AUTOSAR XML (schema 4-2-1)
package /RootP_ASWC_A7D2
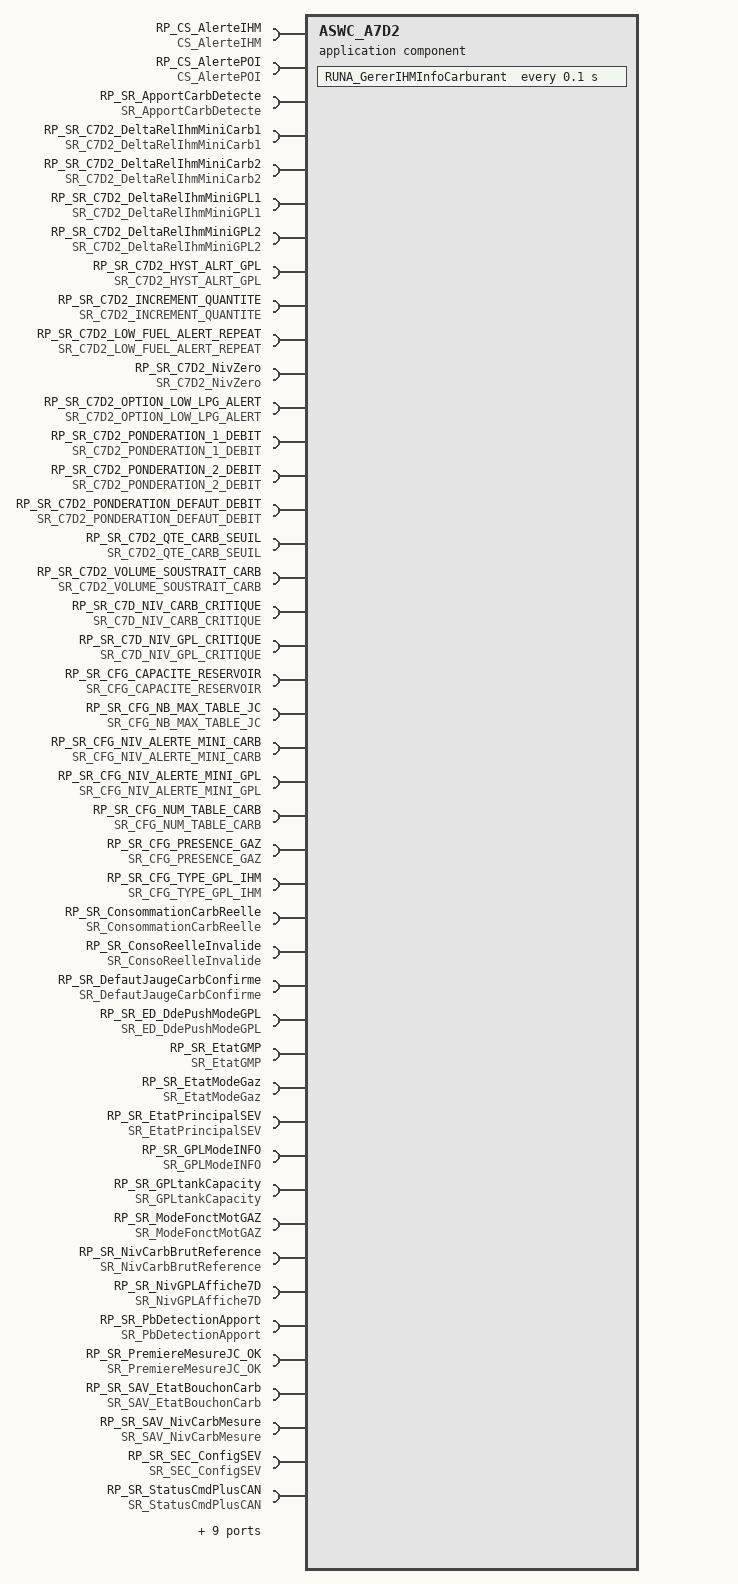
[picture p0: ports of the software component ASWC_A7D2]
  application sw component type ASWC_A7D2
    9 x provide/require port:
      PRP_SR_CapaciteReservoirJCA: nonqueued-receiver-com-spec{data-element=CapaciteReservoirJCA, enable-update=0, handle-data-status=1, handle-never-received=0, init-value=CONST_tBYTE_0:0}, provided-required-interface=SR_CapaciteReservoirJCA
      PRP_SR_DdeVoyMiniCarburant: nonqueued-receiver-com-spec{data-element=DdeVoyMiniCarburant, enable-update=0, handle-data-status=1, handle-never-received=0, init-value=CONST_tLOG_0:0}, provided-required-interface=SR_DdeVoyMiniCarburant
      PRP_SR_DdeVoyMiniCarburantClig: nonqueued-receiver-com-spec{data-element=DdeVoyMiniCarburantClig, enable-update=0, handle-data-status=1, handle-never-received=0, init-value=CONST_t_cDemande_0:0}, provided-required-interface=SR_DdeVoyMiniCarburantClig
      PRP_SR_MiniCarburant: nonqueued-receiver-com-spec{data-element=MiniCarburant, enable-update=0, handle-data-status=1, handle-never-received=0, init-value=CONST_tLOG_0:0}, provided-required-interface=SR_MiniCarburant
      PRP_SR_MiniGPL: nonqueued-receiver-com-spec{data-element=MiniGPL, enable-update=0, handle-data-status=1, handle-never-received=0, init-value=CONST_tLOG_0:0}, provided-required-interface=SR_MiniGPL
      PRP_SR_MiniGPLCritique: nonqueued-receiver-com-spec{data-element=MiniGPLCritique, enable-update=0, handle-data-status=1, handle-never-received=0, init-value=CONST_tLOG_0:0}, provided-required-interface=SR_MiniGPLCritique
      PRP_SR_NivCarbAfficheVersCmb: nonqueued-receiver-com-spec{data-element=NivCarbAfficheVersCmb, enable-update=0, handle-data-status=1, handle-never-received=0, init-value=CONST_tBYTE_0:0}, provided-required-interface=SR_NivCarbAfficheVersCmb
      PRP_SR_NivCarbMesureConverti: nonqueued-receiver-com-spec{data-element=NivCarbMesureConverti, enable-update=0, handle-data-status=1, handle-never-received=0, init-value=CONST_tBYTE_0:0}, provided-required-interface=SR_NivCarbMesureConverti
      PRP_SR_SAV_NivCarbAffiche: nonqueued-receiver-com-spec{data-element=SAV_NivCarbAffiche, enable-update=0, handle-data-status=1, handle-never-received=0, init-value=CONST_tWORD_0xFFFF:65535}, provided-required-interface=SR_SAV_NivCarbAffiche
    53 x require port:
      RP_CS_AlerteIHM: required-interface=CS_AlerteIHM
      RP_CS_AlertePOI: required-interface=CS_AlertePOI
      RP_SR_ApportCarbDetecte: nonqueued-receiver-com-spec{data-element=ApportCarbDetecte, enable-update=0, handle-data-status=1, handle-never-received=0, init-value=CONST_tLOG_0:0}, required-interface=SR_ApportCarbDetecte
      RP_SR_C7D2_DeltaRelIhmMiniCarb1: nonqueued-receiver-com-spec{data-element=C7D2_DeltaRelIhmMiniCarb1, enable-update=0, handle-data-status=1, handle-never-received=0, init-value=CONST_t_C7D2_DeltaRelIhmMiniCarb1_50:50}, required-interface=SR_C7D2_DeltaRelIhmMiniCarb1
      RP_SR_C7D2_DeltaRelIhmMiniCarb2: nonqueued-receiver-com-spec{data-element=C7D2_DeltaRelIhmMiniCarb2, enable-update=0, handle-data-status=1, handle-never-received=0, init-value=CONST_t_C7D2_DeltaRelIhmMiniCarb2_25:25}, required-interface=SR_C7D2_DeltaRelIhmMiniCarb2
      RP_SR_C7D2_DeltaRelIhmMiniGPL1: nonqueued-receiver-com-spec{data-element=C7D2_DeltaRelIhmMiniGPL1, enable-update=0, handle-data-status=1, handle-never-received=0, init-value=CONST_tBYTE_50:50}, required-interface=SR_C7D2_DeltaRelIhmMiniGPL1
      RP_SR_C7D2_DeltaRelIhmMiniGPL2: nonqueued-receiver-com-spec{data-element=C7D2_DeltaRelIhmMiniGPL2, enable-update=0, handle-data-status=1, handle-never-received=0, init-value=CONST_tBYTE_25:25}, required-interface=SR_C7D2_DeltaRelIhmMiniGPL2
      RP_SR_C7D2_HYST_ALRT_GPL: nonqueued-receiver-com-spec{data-element=C7D2_HYST_ALRT_GPL, enable-update=0, handle-data-status=1, handle-never-received=0, init-value=CONST_t_C7D2_HYST_ALRT_GPL_2:2}, required-interface=SR_C7D2_HYST_ALRT_GPL
      RP_SR_C7D2_INCREMENT_QUANTITE: nonqueued-receiver-com-spec{data-element=C7D2_INCREMENT_QUANTITE, enable-update=0, handle-data-status=1, handle-never-received=0, init-value=CONST_tBYTE_37:37}, required-interface=SR_C7D2_INCREMENT_QUANTITE
      RP_SR_C7D2_LOW_FUEL_ALERT_REPEAT: nonqueued-receiver-com-spec{data-element=C7D2_LOW_FUEL_ALERT_REPEAT, enable-update=0, handle-data-status=1, handle-never-received=0, init-value=CONST_tLOG_0:0}, required-interface=SR_C7D2_LOW_FUEL_ALERT_REPEAT
      RP_SR_C7D2_NivZero: nonqueued-receiver-com-spec{data-element=C7D2_NivZero, enable-update=0, handle-data-status=1, handle-never-received=0, init-value=CONST_tBYTE_0:0}, required-interface=SR_C7D2_NivZero
      RP_SR_C7D2_OPTION_LOW_LPG_ALERT: nonqueued-receiver-com-spec{data-element=C7D2_OPTION_LOW_LPG_ALERT, enable-update=0, handle-data-status=1, handle-never-received=0, init-value=CONST_C7D2_OPTION_LOW_LPG_ALERT_t_cPosIdent_cPosIdent_Absent:0}, required-interface=SR_C7D2_OPTION_LOW_LPG_ALERT
      RP_SR_C7D2_PONDERATION_1_DEBIT: nonqueued-receiver-com-spec{data-element=C7D2_PONDERATION_1_DEBIT, enable-update=0, handle-data-status=1, handle-never-received=0, init-value=CONST_tBYTE_18:18}, required-interface=SR_C7D2_PONDERATION_1_DEBIT
      RP_SR_C7D2_PONDERATION_2_DEBIT: nonqueued-receiver-com-spec{data-element=C7D2_PONDERATION_2_DEBIT, enable-update=0, handle-data-status=1, handle-never-received=0, init-value=CONST_tBYTE_7:7}, required-interface=SR_C7D2_PONDERATION_2_DEBIT
      RP_SR_C7D2_PONDERATION_DEFAUT_DEBIT: nonqueued-receiver-com-spec{data-element=C7D2_PONDERATION_DEFAUT_DEBIT, enable-update=0, handle-data-status=1, handle-never-received=0, init-value=CONST_tBYTE_13:13}, required-interface=SR_C7D2_PONDERATION_DEFAUT_DEBIT
      RP_SR_C7D2_QTE_CARB_SEUIL: nonqueued-receiver-com-spec{data-element=C7D2_QTE_CARB_SEUIL, enable-update=0, handle-data-status=1, handle-never-received=0, init-value=CONST_tWORD_1250:1250}, required-interface=SR_C7D2_QTE_CARB_SEUIL
      RP_SR_C7D2_VOLUME_SOUSTRAIT_CARB: nonqueued-receiver-com-spec{data-element=C7D2_VOLUME_SOUSTRAIT_CARB, enable-update=0, handle-data-status=1, handle-never-received=0, init-value=CONST_tBYTE_0:0}, required-interface=SR_C7D2_VOLUME_SOUSTRAIT_CARB
      RP_SR_C7D_NIV_CARB_CRITIQUE: nonqueued-receiver-com-spec{data-element=C7D_NIV_CARB_CRITIQUE, enable-update=0, handle-data-status=1, handle-never-received=0, init-value=CONST_t_C7D_NIV_CARB_CRITIQUE_4:4}, required-interface=SR_C7D_NIV_CARB_CRITIQUE
      RP_SR_C7D_NIV_GPL_CRITIQUE: nonqueued-receiver-com-spec{data-element=C7D_NIV_GPL_CRITIQUE, enable-update=0, handle-data-status=1, handle-never-received=0, init-value=CONST_tBYTE_7:7}, required-interface=SR_C7D_NIV_GPL_CRITIQUE
      RP_SR_CFG_CAPACITE_RESERVOIR: nonqueued-receiver-com-spec{data-element=CFG_CAPACITE_RESERVOIR, enable-update=0, handle-data-status=1, handle-never-received=0, init-value=CONST_tBYTE_50:50}, required-interface=SR_CFG_CAPACITE_RESERVOIR
      RP_SR_CFG_NB_MAX_TABLE_JC: nonqueued-receiver-com-spec{data-element=CFG_NB_MAX_TABLE_JC, enable-update=0, handle-data-status=1, handle-never-received=0, init-value=CONST_tBYTE_15:15}, required-interface=SR_CFG_NB_MAX_TABLE_JC
      RP_SR_CFG_NIV_ALERTE_MINI_CARB: nonqueued-receiver-com-spec{data-element=CFG_NIV_ALERTE_MINI_CARB, enable-update=0, handle-data-status=1, handle-never-received=0, init-value=CONST_tBYTE_20:20}, required-interface=SR_CFG_NIV_ALERTE_MINI_CARB
      RP_SR_CFG_NIV_ALERTE_MINI_GPL: nonqueued-receiver-com-spec{data-element=CFG_NIV_ALERTE_MINI_GPL, enable-update=0, handle-data-status=1, handle-never-received=0, init-value=CONST_tBYTE_16:16}, required-interface=SR_CFG_NIV_ALERTE_MINI_GPL
      RP_SR_CFG_NUM_TABLE_CARB: nonqueued-receiver-com-spec{data-element=CFG_NUM_TABLE_CARB, enable-update=0, handle-data-status=1, handle-never-received=0, init-value=CONST_tBYTE_255:255}, required-interface=SR_CFG_NUM_TABLE_CARB
      RP_SR_CFG_PRESENCE_GAZ: nonqueued-receiver-com-spec{data-element=CFG_PRESENCE_GAZ, enable-update=0, handle-data-status=1, handle-never-received=0, init-value=CONST_tLOG_0:0}, required-interface=SR_CFG_PRESENCE_GAZ
      RP_SR_CFG_TYPE_GPL_IHM: nonqueued-receiver-com-spec{data-element=CFG_TYPE_GPL_IHM, enable-update=0, handle-data-status=1, handle-never-received=0, init-value=CONST_t_cIHM_0:0}, required-interface=SR_CFG_TYPE_GPL_IHM
      RP_SR_ConsommationCarbReelle: nonqueued-receiver-com-spec{data-element=ConsommationCarbReelle, enable-update=0, handle-data-status=1, handle-never-received=0, init-value=CONST_tBYTE_0:0}, required-interface=SR_ConsommationCarbReelle
      RP_SR_ConsoReelleInvalide: nonqueued-receiver-com-spec{data-element=ConsoReelleInvalide, enable-update=0, handle-data-status=1, handle-never-received=0, init-value=CONST_tLOG_0:0}, required-interface=SR_ConsoReelleInvalide
      RP_SR_DefautJaugeCarbConfirme: nonqueued-receiver-com-spec{data-element=DefautJaugeCarbConfirme, enable-update=0, handle-data-status=1, handle-never-received=0, init-value=CONST_DefautJaugeCarbConfirme_t_cSDF_Defaut_cSDF_DefautAbsent:105}, required-interface=SR_DefautJaugeCarbConfirme
      RP_SR_ED_DdePushModeGPL: nonqueued-receiver-com-spec{data-element=ED_DdePushModeGPL, enable-update=0, handle-data-status=1, handle-never-received=0, init-value=CONST_tLOG_0:0}, required-interface=SR_ED_DdePushModeGPL
      RP_SR_EtatGMP: nonqueued-receiver-com-spec{data-element=EtatGMP, enable-update=0, handle-data-status=1, handle-never-received=0, init-value=CONST_EtatGMP_t_GM_GMP_GM_GMPCoupe:1}, required-interface=SR_EtatGMP
      RP_SR_EtatModeGaz: nonqueued-receiver-com-spec{data-element=EtatModeGaz, enable-update=0, handle-data-status=1, handle-never-received=0, init-value=CONST_EtatModeGaz_t_EtatModeGaz_Essence:7}, required-interface=SR_EtatModeGaz
      RP_SR_EtatPrincipalSEV: nonqueued-receiver-com-spec{data-element=EtatPrincipalSEV, enable-update=0, handle-data-status=1, handle-never-received=0, init-value=CONST_EtatPrincipalSEV_t_SEV_SEV_Arret:105}, required-interface=SR_EtatPrincipalSEV
      RP_SR_GPLModeINFO: nonqueued-receiver-com-spec{data-element=GPLModeINFO, enable-update=0, handle-data-status=1, handle-never-received=0, init-value=CONST_t_e_0_0:0}, required-interface=SR_GPLModeINFO
      RP_SR_GPLtankCapacity: nonqueued-receiver-com-spec{data-element=GPLtankCapacity, enable-update=0, handle-data-status=1, handle-never-received=0, init-value=CONST_tBYTE_0:0}, required-interface=SR_GPLtankCapacity
      RP_SR_ModeFonctMotGAZ: nonqueued-receiver-com-spec{data-element=ModeFonctMotGAZ, enable-update=0, handle-data-status=1, handle-never-received=0, init-value=CONST_t_cModeFonctMotGAZ_0x07:7}, required-interface=SR_ModeFonctMotGAZ
      RP_SR_NivCarbBrutReference: nonqueued-receiver-com-spec{data-element=NivCarbBrutReference, enable-update=0, handle-data-status=1, handle-never-received=0, init-value=CONST_tWORD_0:0}, required-interface=SR_NivCarbBrutReference
      RP_SR_NivGPLAffiche7D: nonqueued-receiver-com-spec{data-element=NivGPLAffiche7D, enable-update=0, handle-data-status=1, handle-never-received=0, init-value=CONST_tBYTE_0:0}, required-interface=SR_NivGPLAffiche7D
      RP_SR_PbDetectionApport: nonqueued-receiver-com-spec{data-element=PbDetectionApport, enable-update=0, handle-data-status=1, handle-never-received=0, init-value=CONST_tLOG_0:0}, required-interface=SR_PbDetectionApport
      RP_SR_PremiereMesureJC_OK: nonqueued-receiver-com-spec{data-element=PremiereMesureJC_OK, enable-update=0, handle-data-status=1, handle-never-received=0, init-value=CONST_PremiereMesureJC_OK_t_cSDF_Mesure_cSDF_MesureNonRealisee:105}, required-interface=SR_PremiereMesureJC_OK
      RP_SR_SAV_EtatBouchonCarb: nonqueued-receiver-com-spec{data-element=SAV_EtatBouchonCarb, enable-update=0, handle-data-status=1, handle-never-received=0, init-value=CONST_tLOG_0:0}, required-interface=SR_SAV_EtatBouchonCarb
      RP_SR_SAV_NivCarbMesure: nonqueued-receiver-com-spec{data-element=SAV_NivCarbMesure, enable-update=0, handle-data-status=1, handle-never-received=0, init-value=CONST_tWORD_0:0}, required-interface=SR_SAV_NivCarbMesure
      RP_SR_SEC_ConfigSEV: nonqueued-receiver-com-spec{data-element=SEC_ConfigSEV, enable-update=0, handle-data-status=1, handle-never-received=0, init-value=CONST_t_cCSEV_4:4}, required-interface=SR_SEC_ConfigSEV
      RP_SR_StatusCmdPlusCAN: nonqueued-receiver-com-spec{data-element=StatusCmdPlusCAN, enable-update=0, handle-data-status=1, handle-never-received=0, init-value=CONST_StatusCmdPlusCAN_t_cCmdPlusCAN_PLUSCAN_UNDEFINED:3}, required-interface=SR_StatusCmdPlusCAN
      RP_SR_T7D2_DeltaRelIhmMiniCarbZero: nonqueued-receiver-com-spec{data-element=T7D2_DeltaRelIhmMiniCarbZero, enable-update=0, handle-data-status=1, handle-never-received=0, init-value=CONST_t_T7D2_DeltaRelIhmMiniCarbZero_60:60}, required-interface=SR_T7D2_DeltaRelIhmMiniCarbZero
      RP_SR_T7D2_DUREE_MIN_PUSH_GPL: nonqueued-receiver-com-spec{data-element=T7D2_DUREE_MIN_PUSH_GPL, enable-update=0, handle-data-status=1, handle-never-received=0, init-value=CONST_tBYTE_10:10}, required-interface=SR_T7D2_DUREE_MIN_PUSH_GPL
      RP_SR_T7D2_FAILURE_PUSH_GPL: nonqueued-receiver-com-spec{data-element=T7D2_FAILURE_PUSH_GPL, enable-update=0, handle-data-status=1, handle-never-received=0, init-value=CONST_t_T7D2_FAILURE_PUSH_GPL_20:20}, required-interface=SR_T7D2_FAILURE_PUSH_GPL
      RP_SR_T7D2_FILTRE_LED_GPL: nonqueued-receiver-com-spec{data-element=T7D2_FILTRE_LED_GPL, enable-update=0, handle-data-status=1, handle-never-received=0, init-value=CONST_tBYTE_20:20}, required-interface=SR_T7D2_FILTRE_LED_GPL
      RP_SR_T7D2_FILTRE_PUSH_GPL: nonqueued-receiver-com-spec{data-element=T7D2_FILTRE_PUSH_GPL, enable-update=0, handle-data-status=1, handle-never-received=0, init-value=CONST_tBYTE_20:20}, required-interface=SR_T7D2_FILTRE_PUSH_GPL
      RP_SR_T7D2_TEMPO_FILTRAGE_IHM_MINICARB: nonqueued-receiver-com-spec{data-element=T7D2_TEMPO_FILTRAGE_IHM_MINICARB, enable-update=0, handle-data-status=1, handle-never-received=0, init-value=CONST_t_T7D2_TEMPO_FILTRAGE_IHM_MINICARB_10:10}, required-interface=SR_T7D2_TEMPO_FILTRAGE_IHM_MINICARB
      RP_SR_T7D2_TEMPO_LISSAGE: nonqueued-receiver-com-spec{data-element=T7D2_TEMPO_LISSAGE, enable-update=0, handle-data-status=1, handle-never-received=0, init-value=CONST_tBYTE_22:22}, required-interface=SR_T7D2_TEMPO_LISSAGE
      RP_SR_ToggleAcqJaugeRealisee: nonqueued-receiver-com-spec{data-element=ToggleAcqJaugeRealisee, enable-update=0, handle-data-status=1, handle-never-received=0, init-value=CONST_tLOG_0:0}, required-interface=SR_ToggleAcqJaugeRealisee
      ASWC_A7D2_MSI: required-interface=AppModeInterface
    behavior IB_ASWC_A7D2: data-type-mapping=ApplicationModeMapping, handle-termination-and-restart=NO-SUPPORT
      ar-typed-per-instance-memorys:
        84 x data:
          PA72D_TempoDdePushModeEnablePushGPL: type=tDWORD, init-value=CONST_tDWORD_0:0
          PA7D2_AlerteNiveauMini: type=tWORD, init-value=CONST_tWORD_0:0
          PA7D2_AlerteNiveauMiniCritique: type=tWORD, init-value=CONST_tWORD_0:0
          PA7D2_AlertGPLDenied: type=tLOG, init-value=CONST_tLOG_0:0
          PA7D2_AppCarbDetPrec: type=tLOG, init-value=CONST_tLOG_0:0
          PA7D2_AutorAlerteNivMin: type=tLOG, init-value=CONST_tLOG_0:0
          PA7D2_BasculeEssenceGaz: type=tLOG, init-value=CONST_tLOG_0:0
          PA7D2_BasculeGazEssence: type=tLOG, init-value=CONST_tLOG_0:0
          PA7D2_ChangeLEDGPL: type=tLOG, init-value=CONST_tLOG_0:0
          PA7D2_CoeffPond: type=tBYTE, init-value=CONST_tBYTE_0:0
          PA7D2_CommutEssenceGAZ: type=tLOG, init-value=CONST_tLOG_0:0
          PA7D2_CommutGazEssence: type=tLOG, init-value=CONST_tLOG_0:0
          PA7D2_CondPassageGazEssence: type=tLOG, init-value=CONST_tLOG_1:1
          PA7D2_CondRtOK: type=tLOG, init-value=CONST_tLOG_0:0
          PA7D2_ConsoCarbReellePrec: type=tBYTE, init-value=CONST_tBYTE_0:0
          PA7D2_CptDeltaNivCarb1: type=tWORD, init-value=CONST_tWORD_0:0
          PA7D2_CptDeltaNivCarb2: type=tWORD, init-value=CONST_tWORD_0:0
          PA7D2_CptLissage: type=tBYTE, init-value=CONST_tBYTE_0:0
          PA7D2_CptTempoAppa_PushModeGPL: type=tWORD, init-value=CONST_tWORD_0:0
          PA7D2_CptTempoDisp_PushModeGPL: type=tWORD, init-value=CONST_tWORD_0:0
          PA7D2_DansEtatRecopie: type=tLOG, init-value=CONST_tLOG_0:0
          PA7D2_DdeForcMAJNivCarbPrec: type=tLOG, init-value=CONST_tLOG_0:0
          PA7D2_DdePushGPL: type=tLOG, init-value=CONST_tLOG_0:0
          PA7D2_DdePushGPLPrec: type=tLOG, init-value=CONST_tLOG_0:0
          PA7D2_DdeReinitNivCarbPrec: type=tLOG, init-value=CONST_tLOG_0:0
          PA7D2_DefautPrec_PushModeGPL: type=tBYTE, init-value=CONST_tBYTE_0:0
          PA7D2_DefautPushGPL: type=tLOG, init-value=CONST_tLOG_0:0
          PA7D2_DeltaConsoMemorized: type=tLOG, init-value=CONST_tLOG_0:0
          PA7D2_DeltaRelIHMmini1: type=tWORD, init-value=CONST_tWORD_0:0
          PA7D2_DeltaRelIHMmini2: type=tWORD, init-value=CONST_tWORD_0:0
          PA7D2_EnfoncePushGPL: type=tLOG, init-value=CONST_tLOG_0:0
          PA7D2_EtatModeGazPrec: type=tBYTE, init-value=CONST_tBYTE_7:7
          PA7D2_EtatPrincipalSEVPrec: type=tBYTE, init-value=CONST_tBYTE_0:0
          PA7D2_EtatSysPrecEnAPC: type=tLOG, init-value=CONST_tLOG_0:0
          PA7D2_FiltreF3: type=tBYTE, init-value=CONST_tBYTE_0:0
          PA7D2_FlagAlerteJGCAMiniGPL: type=tLOG, init-value=CONST_tLOG_0:0
          PA7D2_FlagAlerteMiniCarburant: type=tLOG, init-value=CONST_tLOG_0:0
          PA7D2_FlagAlerteRelancee: type=tLOG, init-value=CONST_tLOG_1:1
          PA7D2_FlagAlerteRelanceeNivCrit: type=tLOG, init-value=CONST_tLOG_1:1
          PA7D2_FlagAlerteRelanceeNivZero: type=tLOG, init-value=CONST_tLOG_1:1
          PA7D2_FlagAlrtMiniCarbu: type=tLOG, init-value=CONST_tLOG_0:0
          PA7D2_FlagDoubleDefVu: type=tLOG, init-value=CONST_tLOG_0:0
          PA7D2_FLAG_INDICATEURMODE: type=tLOG, init-value=CONST_tLOG_0:0
          PA7D2_GPLModeINFOPrec: type=tBYTE, init-value=CONST_tBYTE_0:0
          PA7D2_HysteresisAlert: type=tWORD, init-value=CONST_tWORD_0:0
          PA7D2_IdentifiantAlert: type=tWORD, init-value=CONST_tWORD_0:0
          PA7D2_LEDModeGPL: type=tBYTE, init-value=CONST_tBYTE_0:0
          PA7D2_MiniCarburantCritique: type=tLOG, init-value=CONST_tLOG_0x0:0
          PA7D2_ModeEssence: type=tLOG, init-value=CONST_tLOG_0:0
          PA7D2_ModeFctMotGAZPrec: type=tBYTE, init-value=CONST_tBYTE_0x7:7
          PA7D2_ModeFonctMotGAZPrec: type=tBYTE, init-value=CONST_tBYTE_0:0
          PA7D2_ModeGAZ: type=tLOG, init-value=CONST_tLOG_0:0
          PA7D2_NivCarbAfficheGeneral: type=tWORD, init-value=CONST_tWORD_0:0
          PA7D2_NivCarbAffichePrec: type=tWORD, init-value=CONST_tWORD_0xFFFF:65535
          PA7D2_NivCarbAfficheValide: type=tWORD, init-value=CONST_tWORD_0:0
          PA7D2_NivCarbBrutReferenceValide: type=tWORD, init-value=CONST_tWORD_0:0
          PA7D2_NivCarbLisseValide: type=tWORD, init-value=CONST_tWORD_0:0
          PA7D2_NivCarbMesureValide: type=tWORD, init-value=CONST_tWORD_0:0
          PA7D2_NiveauMiniAtteint: type=tLOG, init-value=CONST_tLOG_0:0
          PA7D2_NivGPLAfficheenLitres: type=tWORD, init-value=CONST_tWORD_0:0
          PA7D2_OldAPCElectrique: type=tBYTE, init-value=CONST_tBYTE_0:0
          PA7D2_OldStateDef2_PushModeGPL: type=tBYTE, init-value=CONST_tBYTE_0:0
          PA7D2_PassageAPCVu: type=tLOG, init-value=CONST_tLOG_0:0
          PA7D2_Periode_LEDModeGPL_Prec: type=tWORD, init-value=CONST_tWORD_1000:1000
          PA7D2_PrecModeEssence: type=tLOG, init-value=CONST_tLOG_0:0
          PA7D2_PrecModeGAZ: type=tLOG, init-value=CONST_tLOG_0:0
          PA7D2_Premiere_Determination_Delta_Conso: type=tLOG, init-value=CONST_tLOG_0:0
          PA7D2_RC_LEDModeGPL_IO_Prec: type=tBYTE, init-value=CONST_tBYTE_0:0
          PA7D2_ResetBSIDetecte: type=tLOG, init-value=CONST_tLOG_0:0
          PA7D2_ResetBSITraite: type=tLOG, init-value=CONST_tLOG_0:0
          PA7D2_SAV_DefautJaugeCarbConfirmePrec: type=tBYTE, init-value=CONST_tBYTE_0x69:105
          PA7D2_SAV_DeltaConso: type=tWORD, init-value=CONST_tWORD_0:0
          PA7D2_SAV_DeltaConso_MEM_GAZ: type=tWORD, init-value=CONST_tWORD_0:0
          PA7D2_SAV_DeltaConsoPrec: type=tWORD, init-value=CONST_tWORD_0:0
          PA7D2_SAV_NivCarbLisse: type=tWORD, init-value=CONST_tWORD_0:0
          PA7D2_SAV_PremiereInitAffOK: type=tLOG, init-value=CONST_tLOG_0:0
          PA7D2_SAV_PremiereInitLisseOK: type=tLOG, init-value=CONST_tLOG_0:0
          PA7D2_TempoChangeLEDGPL: type=tDWORD, init-value=CONST_tDWORD_0:0
          PA7D2_TempoDureePushGPL: type=tDWORD, init-value=CONST_tDWORD_0:0
          PA7D2_TempoFiltrageIHM: type=tBYTE, init-value=CONST_tBYTE_0xFF:255
          PA7D2_TempoLissage: type=tBYTE, init-value=CONST_tBYTE_0:0
          PA7D2_TempoPriseEnCompteEnfonce: type=tWORD, init-value=CONST_tWORD_0:0
          PA7D2_TempoRelanceAlerteNivCarb: type=tWORD, init-value=CONST_tWORD_0:0
          PA7D2_ToggleAcqJCPrec: type=tLOG, init-value=CONST_tLOG_0:0
      timing event RUNA_GererIHMInfoCarburant_Cyclic: start-on-event=RUNA_GererIHMInfoCarburant, period=0.1
        disabled-mode:
          ASWC_A7D2_MSI.AppMode.APP_WAKEUP
          ASWC_A7D2_MSI.AppMode.APP_OFF
          ASWC_A7D2_MSI.AppMode.APP_SYNC_INIT
          ASWC_A7D2_MSI.AppMode.APP_CONFIG
      4 x runnable:
        RUNA_GererIHMInfoCarburant
          data-read-access:
            54 x access:
              dra_RP_SR_ApportCarbDetecte_ApportCarbDetecte: accessed-variable=RP_SR_ApportCarbDetecte.ApportCarbDetecte
              dra_RP_SR_ConsommationCarbReelle_ConsommationCarbReelle: accessed-variable=RP_SR_ConsommationCarbReelle.ConsommationCarbReelle
              dra_RP_SR_ConsoReelleInvalide_ConsoReelleInvalide: accessed-variable=RP_SR_ConsoReelleInvalide.ConsoReelleInvalide
              dra_RP_SR_DefautJaugeCarbConfirme_DefautJaugeCarbConfirme: accessed-variable=RP_SR_DefautJaugeCarbConfirme.DefautJaugeCarbConfirme
              dra_RP_SR_ED_DdePushModeGPL_ED_DdePushModeGPL: accessed-variable=RP_SR_ED_DdePushModeGPL.ED_DdePushModeGPL
              dra_RP_SR_EtatGMP_EtatGMP: accessed-variable=RP_SR_EtatGMP.EtatGMP
              dra_RP_SR_EtatModeGaz_EtatModeGaz: accessed-variable=RP_SR_EtatModeGaz.EtatModeGaz
              dra_RP_SR_EtatPrincipalSEV_EtatPrincipalSEV: accessed-variable=RP_SR_EtatPrincipalSEV.EtatPrincipalSEV
              dra_RP_SR_GPLModeINFO_GPLModeINFO: accessed-variable=RP_SR_GPLModeINFO.GPLModeINFO
              dra_RP_SR_GPLtankCapacity_GPLtankCapacity: accessed-variable=RP_SR_GPLtankCapacity.GPLtankCapacity
              dra_RP_SR_ModeFonctMotGAZ_ModeFonctMotGAZ: accessed-variable=RP_SR_ModeFonctMotGAZ.ModeFonctMotGAZ
              dra_RP_SR_NivCarbBrutReference_NivCarbBrutReference: accessed-variable=RP_SR_NivCarbBrutReference.NivCarbBrutReference
              dra_RP_SR_NivGPLAffiche7D_NivGPLAffiche7D: accessed-variable=RP_SR_NivGPLAffiche7D.NivGPLAffiche7D
              dra_RP_SR_PbDetectionApport_PbDetectionApport: accessed-variable=RP_SR_PbDetectionApport.PbDetectionApport
              dra_RP_SR_PremiereMesureJC_OK_PremiereMesureJC_OK: accessed-variable=RP_SR_PremiereMesureJC_OK.PremiereMesureJC_OK
              dra_RP_SR_SAV_EtatBouchonCarb_SAV_EtatBouchonCarb: accessed-variable=RP_SR_SAV_EtatBouchonCarb.SAV_EtatBouchonCarb
              dra_RP_SR_SAV_NivCarbMesure_SAV_NivCarbMesure: accessed-variable=RP_SR_SAV_NivCarbMesure.SAV_NivCarbMesure
              dra_RP_SR_SEC_ConfigSEV_SEC_ConfigSEV: accessed-variable=RP_SR_SEC_ConfigSEV.SEC_ConfigSEV
              dra_RP_SR_ToggleAcqJaugeRealisee_ToggleAcqJaugeRealisee: accessed-variable=RP_SR_ToggleAcqJaugeRealisee.ToggleAcqJaugeRealisee
              dra_RP_SR_C7D2_DeltaRelIhmMiniCarb1_C7D2_DeltaRelIhmMiniCarb1: accessed-variable=RP_SR_C7D2_DeltaRelIhmMiniCarb1.C7D2_DeltaRelIhmMiniCarb1
              dra_RP_SR_C7D2_DeltaRelIhmMiniCarb2_C7D2_DeltaRelIhmMiniCarb2: accessed-variable=RP_SR_C7D2_DeltaRelIhmMiniCarb2.C7D2_DeltaRelIhmMiniCarb2
              dra_RP_SR_C7D2_DeltaRelIhmMiniGPL1_C7D2_DeltaRelIhmMiniGPL1: accessed-variable=RP_SR_C7D2_DeltaRelIhmMiniGPL1.C7D2_DeltaRelIhmMiniGPL1
              dra_RP_SR_C7D2_DeltaRelIhmMiniGPL2_C7D2_DeltaRelIhmMiniGPL2: accessed-variable=RP_SR_C7D2_DeltaRelIhmMiniGPL2.C7D2_DeltaRelIhmMiniGPL2
              dra_RP_SR_C7D2_HYST_ALRT_GPL_C7D2_HYST_ALRT_GPL: accessed-variable=RP_SR_C7D2_HYST_ALRT_GPL.C7D2_HYST_ALRT_GPL
              dra_RP_SR_C7D2_INCREMENT_QUANTITE_C7D2_INCREMENT_QUANTITE: accessed-variable=RP_SR_C7D2_INCREMENT_QUANTITE.C7D2_INCREMENT_QUANTITE
              dra_RP_SR_C7D2_LOW_FUEL_ALERT_REPEAT_C7D2_LOW_FUEL_ALERT_REPEAT: accessed-variable=RP_SR_C7D2_LOW_FUEL_ALERT_REPEAT.C7D2_LOW_FUEL_ALERT_REPEAT
              dra_RP_SR_C7D2_NivZero_C7D2_NivZero: accessed-variable=RP_SR_C7D2_NivZero.C7D2_NivZero
              dra_RP_SR_C7D2_OPTION_LOW_LPG_ALERT_C7D2_OPTION_LOW_LPG_ALERT: accessed-variable=RP_SR_C7D2_OPTION_LOW_LPG_ALERT.C7D2_OPTION_LOW_LPG_ALERT
              dra_RP_SR_C7D2_PONDERATION_1_DEBIT_C7D2_PONDERATION_1_DEBIT: accessed-variable=RP_SR_C7D2_PONDERATION_1_DEBIT.C7D2_PONDERATION_1_DEBIT
              dra_RP_SR_C7D2_PONDERATION_2_DEBIT_C7D2_PONDERATION_2_DEBIT: accessed-variable=RP_SR_C7D2_PONDERATION_2_DEBIT.C7D2_PONDERATION_2_DEBIT
              dra_RP_SR_C7D2_PONDERATION_DEFAUT_DEBIT_C7D2_PONDERATION_DEFAUT_DEBIT: accessed-variable=RP_SR_C7D2_PONDERATION_DEFAUT_DEBIT.C7D2_PONDERATION_DEFAUT_DEBIT
              dra_RP_SR_C7D2_QTE_CARB_SEUIL_C7D2_QTE_CARB_SEUIL: accessed-variable=RP_SR_C7D2_QTE_CARB_SEUIL.C7D2_QTE_CARB_SEUIL
              dra_RP_SR_C7D2_VOLUME_SOUSTRAIT_CARB_C7D2_VOLUME_SOUSTRAIT_CARB: accessed-variable=RP_SR_C7D2_VOLUME_SOUSTRAIT_CARB.C7D2_VOLUME_SOUSTRAIT_CARB
              dra_RP_SR_C7D_NIV_CARB_CRITIQUE_C7D_NIV_CARB_CRITIQUE: accessed-variable=RP_SR_C7D_NIV_CARB_CRITIQUE.C7D_NIV_CARB_CRITIQUE
              dra_RP_SR_C7D_NIV_GPL_CRITIQUE_C7D_NIV_GPL_CRITIQUE: accessed-variable=RP_SR_C7D_NIV_GPL_CRITIQUE.C7D_NIV_GPL_CRITIQUE
              dra_RP_SR_CFG_CAPACITE_RESERVOIR_CFG_CAPACITE_RESERVOIR: accessed-variable=RP_SR_CFG_CAPACITE_RESERVOIR.CFG_CAPACITE_RESERVOIR
              dra_RP_SR_CFG_NB_MAX_TABLE_JC_CFG_NB_MAX_TABLE_JC: accessed-variable=RP_SR_CFG_NB_MAX_TABLE_JC.CFG_NB_MAX_TABLE_JC
              dra_RP_SR_CFG_NIV_ALERTE_MINI_CARB_CFG_NIV_ALERTE_MINI_CARB: accessed-variable=RP_SR_CFG_NIV_ALERTE_MINI_CARB.CFG_NIV_ALERTE_MINI_CARB
              dra_RP_SR_CFG_NIV_ALERTE_MINI_GPL_CFG_NIV_ALERTE_MINI_GPL: accessed-variable=RP_SR_CFG_NIV_ALERTE_MINI_GPL.CFG_NIV_ALERTE_MINI_GPL
              dra_RP_SR_CFG_NUM_TABLE_CARB_CFG_NUM_TABLE_CARB: accessed-variable=RP_SR_CFG_NUM_TABLE_CARB.CFG_NUM_TABLE_CARB
              dra_RP_SR_CFG_PRESENCE_GAZ_CFG_PRESENCE_GAZ: accessed-variable=RP_SR_CFG_PRESENCE_GAZ.CFG_PRESENCE_GAZ
              dra_RP_SR_CFG_TYPE_GPL_IHM_CFG_TYPE_GPL_IHM: accessed-variable=RP_SR_CFG_TYPE_GPL_IHM.CFG_TYPE_GPL_IHM
              dra_RP_SR_T7D2_DeltaRelIhmMiniCarbZero_T7D2_DeltaRelIhmMiniCarbZero: accessed-variable=RP_SR_T7D2_DeltaRelIhmMiniCarbZero.T7D2_DeltaRelIhmMiniCarbZero
              dra_RP_SR_T7D2_TEMPO_FILTRAGE_IHM_MINICARB_T7D2_TEMPO_FILTRAGE_IHM_MINICARB: accessed-variable=RP_SR_T7D2_TEMPO_FILTRAGE_IHM_MINICARB.T7D2_TEMPO_FILTRAGE_IHM_MINICARB
              dra_RP_SR_T7D2_TEMPO_LISSAGE_T7D2_TEMPO_LISSAGE: accessed-variable=RP_SR_T7D2_TEMPO_LISSAGE.T7D2_TEMPO_LISSAGE
              dra_PRP_SR_CapaciteReservoirJCA_CapaciteReservoirJCA: accessed-variable=PRP_SR_CapaciteReservoirJCA.CapaciteReservoirJCA
              dra_PRP_SR_DdeVoyMiniCarburant_DdeVoyMiniCarburant: accessed-variable=PRP_SR_DdeVoyMiniCarburant.DdeVoyMiniCarburant
              dra_PRP_SR_DdeVoyMiniCarburantClig_DdeVoyMiniCarburantClig: accessed-variable=PRP_SR_DdeVoyMiniCarburantClig.DdeVoyMiniCarburantClig
              dra_PRP_SR_MiniCarburant_MiniCarburant: accessed-variable=PRP_SR_MiniCarburant.MiniCarburant
              dra_PRP_SR_MiniGPL_MiniGPL: accessed-variable=PRP_SR_MiniGPL.MiniGPL
              dra_PRP_SR_MiniGPLCritique_MiniGPLCritique: accessed-variable=PRP_SR_MiniGPLCritique.MiniGPLCritique
              dra_PRP_SR_NivCarbAfficheVersCmb_NivCarbAfficheVersCmb: accessed-variable=PRP_SR_NivCarbAfficheVersCmb.NivCarbAfficheVersCmb
              dra_PRP_SR_NivCarbMesureConverti_NivCarbMesureConverti: accessed-variable=PRP_SR_NivCarbMesureConverti.NivCarbMesureConverti
              dra_PRP_SR_SAV_NivCarbAffiche_SAV_NivCarbAffiche: accessed-variable=PRP_SR_SAV_NivCarbAffiche.SAV_NivCarbAffiche
          data-write-access:
            9 x access:
              dwa_PRP_SR_CapaciteReservoirJCA_CapaciteReservoirJCA: accessed-variable=PRP_SR_CapaciteReservoirJCA.CapaciteReservoirJCA
              dwa_PRP_SR_DdeVoyMiniCarburant_DdeVoyMiniCarburant: accessed-variable=PRP_SR_DdeVoyMiniCarburant.DdeVoyMiniCarburant
              dwa_PRP_SR_DdeVoyMiniCarburantClig_DdeVoyMiniCarburantClig: accessed-variable=PRP_SR_DdeVoyMiniCarburantClig.DdeVoyMiniCarburantClig
              dwa_PRP_SR_MiniCarburant_MiniCarburant: accessed-variable=PRP_SR_MiniCarburant.MiniCarburant
              dwa_PRP_SR_MiniGPL_MiniGPL: accessed-variable=PRP_SR_MiniGPL.MiniGPL
              dwa_PRP_SR_MiniGPLCritique_MiniGPLCritique: accessed-variable=PRP_SR_MiniGPLCritique.MiniGPLCritique
              dwa_PRP_SR_NivCarbAfficheVersCmb_NivCarbAfficheVersCmb: accessed-variable=PRP_SR_NivCarbAfficheVersCmb.NivCarbAfficheVersCmb
              dwa_PRP_SR_NivCarbMesureConverti_NivCarbMesureConverti: accessed-variable=PRP_SR_NivCarbMesureConverti.NivCarbMesureConverti
              dwa_PRP_SR_SAV_NivCarbAffiche_SAV_NivCarbAffiche: accessed-variable=PRP_SR_SAV_NivCarbAffiche.SAV_NivCarbAffiche
          sync call sscp_RUNA_GererIHMInfoCarburant_CS_AlerteIHM_Cmd: operation=RP_CS_AlerteIHM.Cmd, timeout=0
          sync call sscp_RUNA_GererIHMInfoCarburant_CS_AlertePOI_Cmd: operation=RP_CS_AlertePOI.Cmd, timeout=0
        RUNS_Routine_ReinitNivCarb_RequestResults
          data-read-access:
            8 x access:
              dra_RP_SR_DefautJaugeCarbConfirme_DefautJaugeCarbConfirme: accessed-variable=RP_SR_DefautJaugeCarbConfirme.DefautJaugeCarbConfirme
              dra_RP_SR_PremiereMesureJC_OK_PremiereMesureJC_OK: accessed-variable=RP_SR_PremiereMesureJC_OK.PremiereMesureJC_OK
              dra_RP_SR_SAV_NivCarbMesure_SAV_NivCarbMesure: accessed-variable=RP_SR_SAV_NivCarbMesure.SAV_NivCarbMesure
              dra_RP_SR_StatusCmdPlusCAN_StatusCmdPlusCAN: accessed-variable=RP_SR_StatusCmdPlusCAN.StatusCmdPlusCAN
              dra_RP_SR_C7D2_VOLUME_SOUSTRAIT_CARB_C7D2_VOLUME_SOUSTRAIT_CARB: accessed-variable=RP_SR_C7D2_VOLUME_SOUSTRAIT_CARB.C7D2_VOLUME_SOUSTRAIT_CARB
              dra_RP_SR_CFG_NB_MAX_TABLE_JC_CFG_NB_MAX_TABLE_JC: accessed-variable=RP_SR_CFG_NB_MAX_TABLE_JC.CFG_NB_MAX_TABLE_JC
              dra_RP_SR_CFG_NUM_TABLE_CARB_CFG_NUM_TABLE_CARB: accessed-variable=RP_SR_CFG_NUM_TABLE_CARB.CFG_NUM_TABLE_CARB
              dra_PRP_SR_SAV_NivCarbAffiche_SAV_NivCarbAffiche: accessed-variable=PRP_SR_SAV_NivCarbAffiche.SAV_NivCarbAffiche
          data-write-access:
            access dwa_PRP_SR_SAV_NivCarbAffiche_SAV_NivCarbAffiche: accessed-variable=PRP_SR_SAV_NivCarbAffiche.SAV_NivCarbAffiche
        RUNS_Routine_ReinitNivCarb_Start
          data-read-access:
            11 x access:
              dra_RP_SR_DefautJaugeCarbConfirme_DefautJaugeCarbConfirme: accessed-variable=RP_SR_DefautJaugeCarbConfirme.DefautJaugeCarbConfirme
              dra_RP_SR_EtatGMP_EtatGMP: accessed-variable=RP_SR_EtatGMP.EtatGMP
              dra_RP_SR_EtatPrincipalSEV_EtatPrincipalSEV: accessed-variable=RP_SR_EtatPrincipalSEV.EtatPrincipalSEV
              dra_RP_SR_PremiereMesureJC_OK_PremiereMesureJC_OK: accessed-variable=RP_SR_PremiereMesureJC_OK.PremiereMesureJC_OK
              dra_RP_SR_SAV_NivCarbMesure_SAV_NivCarbMesure: accessed-variable=RP_SR_SAV_NivCarbMesure.SAV_NivCarbMesure
              dra_RP_SR_SEC_ConfigSEV_SEC_ConfigSEV: accessed-variable=RP_SR_SEC_ConfigSEV.SEC_ConfigSEV
              dra_RP_SR_StatusCmdPlusCAN_StatusCmdPlusCAN: accessed-variable=RP_SR_StatusCmdPlusCAN.StatusCmdPlusCAN
              dra_RP_SR_C7D2_VOLUME_SOUSTRAIT_CARB_C7D2_VOLUME_SOUSTRAIT_CARB: accessed-variable=RP_SR_C7D2_VOLUME_SOUSTRAIT_CARB.C7D2_VOLUME_SOUSTRAIT_CARB
              dra_RP_SR_CFG_NB_MAX_TABLE_JC_CFG_NB_MAX_TABLE_JC: accessed-variable=RP_SR_CFG_NB_MAX_TABLE_JC.CFG_NB_MAX_TABLE_JC
              dra_RP_SR_CFG_NUM_TABLE_CARB_CFG_NUM_TABLE_CARB: accessed-variable=RP_SR_CFG_NUM_TABLE_CARB.CFG_NUM_TABLE_CARB
              dra_PRP_SR_SAV_NivCarbAffiche_SAV_NivCarbAffiche: accessed-variable=PRP_SR_SAV_NivCarbAffiche.SAV_NivCarbAffiche
          data-write-access:
            access dwa_PRP_SR_SAV_NivCarbAffiche_SAV_NivCarbAffiche: accessed-variable=PRP_SR_SAV_NivCarbAffiche.SAV_NivCarbAffiche
        RUNS_Routine_ReinitNivCarb_Stop
package /RootP_Implementatation
  swc implementation Implementatation_ASWC_A7D2: programming-language=C, sw-version=1.0.0, vendor-id=1, behavior=IB_ASWC_A7D2
    code-descriptors:
      code SRC: artifact-descriptors=autosar-engineering-object={short-label=EngObject, category=SWSRC}
    resource consumption Resources
